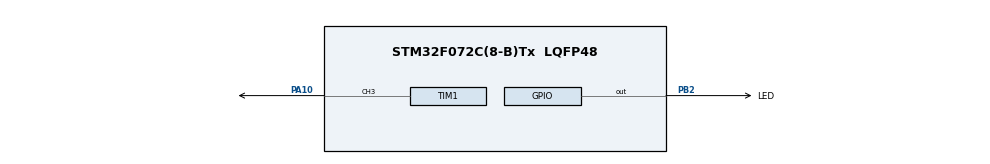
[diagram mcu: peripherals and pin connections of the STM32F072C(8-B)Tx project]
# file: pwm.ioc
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Mcu.Family=STM32F0
Mcu.Name=STM32F072C(8-B)Tx
Mcu.Package=LQFP48
NVIC.TIM1_BRK_UP_TRG_COM_IRQn=true\:0\:0\:false\:false\:true\:true\:true
PA10.Signal=S_TIM1_CH3
PB2.GPIO_Label=LED
PB2.Signal=GPIO_Output
PF0-OSC_IN.Mode=HSE-External-Oscillator
PF0-OSC_IN.Signal=RCC_OSC_IN
PF1-OSC_OUT.Mode=HSE-External-Oscillator
PF1-OSC_OUT.Signal=RCC_OSC_OUT
ProjectManager.HeapSize=0x200
ProjectManager.StackSize=0x400
ProjectManager.TargetToolchain=STM32CubeIDE
SH.S_TIM1_CH3.0=TIM1_CH3,PWM Generation3 CH3
TIM1.Channel-PWM\ Generation3\ CH3=TIM_CHANNEL_3
TIM1.Period=1000-1
TIM1.Prescaler=8-1
board=custom

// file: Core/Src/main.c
/* USER CODE BEGIN Header */
/**
  ******************************************************************************
  * @file           : main.c
  * @brief          : Main program body
  ******************************************************************************
  * @attention
  *
  * <h2><center>&copy; Copyright (c) 2021 STMicroelectronics.
  * All rights reserved.</center></h2>
  *
  * This software component is licensed by ST under BSD 3-Clause license,
  * the "License"; You may not use this file except in compliance with the
  * License. You may obtain a copy of the License at:
  *                        opensource.org/licenses/BSD-3-Clause
  *
  ******************************************************************************
  */
/* USER CODE END Header */
#include "main.h"

TIM_HandleTypeDef htim1;

/* USER CODE BEGIN PV */
int pwm = 0;/*Переменная Ш�?М, подаваемая в таймер*/
int y=0;/*Переменная функции Controller, в которую записывается результат вычисления функции*/
/* USER CODE END PV */

void SystemClock_Config(void);
static void MX_GPIO_Init(void);
static void MX_TIM1_Init(void);
/* USER CODE BEGIN PFP */
int Controller()/*Функция, в которой формируется значение, подаваемое в таймер*/
{
	y=y+1;/*любая математическая функция*/
	if (y>=990)/*Если значение y больше 990,*/
	{
		y=0;/*то обнулим y и начнём счёт заново. Это для избежания переполнения y.*/
	}
	return y;/*Возвращаем вычесленный в функции y*/
}
/* USER CODE END PFP */

int main(void)
{

  /* MCU Configuration--------------------------------------------------------*/

  /* Reset of all peripherals, Initializes the Flash interface and the Systick. */
  HAL_Init();

  /* Configure the system clock */
  SystemClock_Config();

  /* Initialize all configured peripherals */
  MX_GPIO_Init();
  MX_TIM1_Init();
  /* USER CODE BEGIN 2 */
  HAL_TIM_PWM_Start(&htim1, TIM_CHANNEL_3);/*Даём разрешение на работу Ш�?М нашего таймера*/
  HAL_TIM_Base_Start_IT(&htim1);/*Даём разрешение на организацию прерываний*/
  /* USER CODE END 2 */

  /* Infinite loop */
  while (1)
  {

  }
}

void SystemClock_Config(void)
{
  RCC_OscInitTypeDef RCC_OscInitStruct = {0};
  RCC_ClkInitTypeDef RCC_ClkInitStruct = {0};

  /** Initializes the RCC Oscillators according to the specified parameters
  * in the RCC_OscInitTypeDef structure.
  */
  RCC_OscInitStruct.OscillatorType = RCC_OSCILLATORTYPE_HSI;
  RCC_OscInitStruct.HSIState = RCC_HSI_ON;
  RCC_OscInitStruct.HSICalibrationValue = RCC_HSICALIBRATION_DEFAULT;
  RCC_OscInitStruct.PLL.PLLState = RCC_PLL_NONE;
  if (HAL_RCC_OscConfig(&RCC_OscInitStruct) != HAL_OK)
  {
    Error_Handler();
  }
  /** Initializes the CPU, AHB and APB buses clocks
  */
  RCC_ClkInitStruct.ClockType = RCC_CLOCKTYPE_HCLK|RCC_CLOCKTYPE_SYSCLK
                              |RCC_CLOCKTYPE_PCLK1;
  RCC_ClkInitStruct.SYSCLKSource = RCC_SYSCLKSOURCE_HSI;
  RCC_ClkInitStruct.AHBCLKDivider = RCC_SYSCLK_DIV1;
  RCC_ClkInitStruct.APB1CLKDivider = RCC_HCLK_DIV1;

  if (HAL_RCC_ClockConfig(&RCC_ClkInitStruct, FLASH_LATENCY_0) != HAL_OK)
  {
    Error_Handler();
  }
}

static void MX_TIM1_Init(void)
{

  TIM_MasterConfigTypeDef sMasterConfig = {0};
  TIM_OC_InitTypeDef sConfigOC = {0};
  TIM_BreakDeadTimeConfigTypeDef sBreakDeadTimeConfig = {0};

  htim1.Instance = TIM1;
  htim1.Init.Prescaler = 8-1;
  htim1.Init.CounterMode = TIM_COUNTERMODE_UP;
  htim1.Init.Period = 1000;
  htim1.Init.ClockDivision = TIM_CLOCKDIVISION_DIV1;
  htim1.Init.RepetitionCounter = 0;
  htim1.Init.AutoReloadPreload = TIM_AUTORELOAD_PRELOAD_DISABLE;
  if (HAL_TIM_PWM_Init(&htim1) != HAL_OK)
  {
    Error_Handler();
  }
  sMasterConfig.MasterOutputTrigger = TIM_TRGO_RESET;
  sMasterConfig.MasterSlaveMode = TIM_MASTERSLAVEMODE_DISABLE;
  if (HAL_TIMEx_MasterConfigSynchronization(&htim1, &sMasterConfig) != HAL_OK)
  {
    Error_Handler();
  }
  sConfigOC.OCMode = TIM_OCMODE_PWM1;
  sConfigOC.Pulse = 0;
  sConfigOC.OCPolarity = TIM_OCPOLARITY_HIGH;
  sConfigOC.OCNPolarity = TIM_OCNPOLARITY_HIGH;
  sConfigOC.OCFastMode = TIM_OCFAST_DISABLE;
  sConfigOC.OCIdleState = TIM_OCIDLESTATE_RESET;
  sConfigOC.OCNIdleState = TIM_OCNIDLESTATE_RESET;
  if (HAL_TIM_PWM_ConfigChannel(&htim1, &sConfigOC, TIM_CHANNEL_3) != HAL_OK)
  {
    Error_Handler();
  }
  sBreakDeadTimeConfig.OffStateRunMode = TIM_OSSR_DISABLE;
  sBreakDeadTimeConfig.OffStateIDLEMode = TIM_OSSI_DISABLE;
  sBreakDeadTimeConfig.LockLevel = TIM_LOCKLEVEL_OFF;
  sBreakDeadTimeConfig.DeadTime = 0;
  sBreakDeadTimeConfig.BreakState = TIM_BREAK_DISABLE;
  sBreakDeadTimeConfig.BreakPolarity = TIM_BREAKPOLARITY_HIGH;
  sBreakDeadTimeConfig.AutomaticOutput = TIM_AUTOMATICOUTPUT_DISABLE;
  if (HAL_TIMEx_ConfigBreakDeadTime(&htim1, &sBreakDeadTimeConfig) != HAL_OK)
  {
    Error_Handler();
  }
  HAL_TIM_MspPostInit(&htim1);

}

static void MX_GPIO_Init(void)
{
  GPIO_InitTypeDef GPIO_InitStruct = {0};

  /* GPIO Ports Clock Enable */
  __HAL_RCC_GPIOF_CLK_ENABLE();
  __HAL_RCC_GPIOB_CLK_ENABLE();
  __HAL_RCC_GPIOA_CLK_ENABLE();

  /*Configure GPIO pin Output Level */
  HAL_GPIO_WritePin(LED_GPIO_Port, LED_Pin, GPIO_PIN_RESET);

  /*Configure GPIO pin : LED_Pin */
  GPIO_InitStruct.Pin = LED_Pin;
  GPIO_InitStruct.Mode = GPIO_MODE_OUTPUT_PP;
  GPIO_InitStruct.Pull = GPIO_NOPULL;
  GPIO_InitStruct.Speed = GPIO_SPEED_FREQ_LOW;
  HAL_GPIO_Init(LED_GPIO_Port, &GPIO_InitStruct);

}

/* USER CODE BEGIN 4 */
void HAL_TIM_PeriodElapsedCallback(TIM_HandleTypeDef *htim)/*CallBack, вызванный при окончании периода Ш�?М*/
{
	if (htim->Instance == TIM1)/*Проверяем от какого таймера пришёл CallBack*/
	{
		pwm = Controller();/*В переменную pwm запишем результат вычисления функции Controller*/
		htim1.Instance->CCR3 = pwm;/*Запишем значение pwm в регистр CCR3 выбранного таймера, что позволит получить Ш�?М*/
		HAL_GPIO_TogglePin(LED_GPIO_Port, LED_Pin);/*Поменяем состояние светодиода*/
	}
}
/* USER CODE END 4 */

void Error_Handler(void)
{
  __disable_irq();
  while (1)
  {
  }
}

/************************ (C) COPYRIGHT STMicroelectronics *****END OF FILE****/
